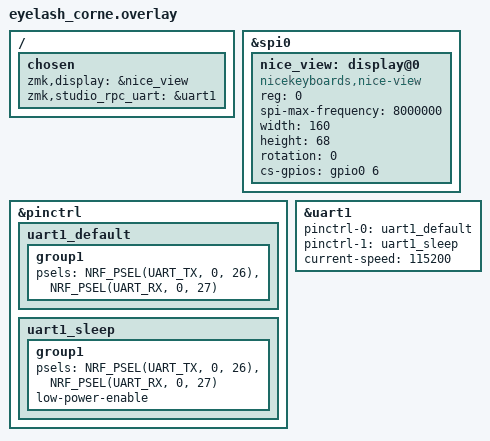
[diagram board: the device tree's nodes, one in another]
/*
 * Copyright (c) 2024 Your Name // Puedes poner tu nombre o dejarlo genérico
 * SPDX-License-Identifier: MIT
 *
 * Overlay para Nicorne Shield habilitando nice!view en SPI0.
 * ASUME que los pines SCK/MOSI/MISO son los definidos en eyelash_corne.dtsi (P0.20, P0.17, P0.25)
 * y que el pin CS es P0.06.
 */

/dts-v1/;
#include <zephyr/dt-bindings/pinctrl/nrf-pinctrl.h> // Necesario para NRF_PSEL
#include <zephyr/dt-bindings/gpio/gpio.h> // Necesario para las flags GPIO

/* Habilita el bus SPI0 (etiquetado como nice_view_spi en el .dtsi)
   y define el dispositivo nice!view conectado a él. */
&spi0 {
    status = "okay"; // Asegura que el bus SPI esté habilitado

    /* Define el dispositivo de pantalla nice!view */
    nice_view: display@0 {
        compatible = "nicekeyboards,nice-view"; // Driver específico nice!view
        reg = <0>;                        // Dirección SPI (normalmente 0 para el primer dispositivo)
        spi-max-frequency = <8000000>;    // Frecuencia SPI (8MHz es común, puedes probar 4MHz si hay problemas)
        width = <160>;                    // Ancho estándar nice!view
        height = <68>;                    // Alto estándar nice!view
        rotation = <0>;                   // Rotación (0, 90, 180, 270) - ajusta si es necesario

        cs-gpios = <&gpio0 6 GPIO_ACTIVE_HIGH>;

        /* Descomenta y ajusta si tu placa tiene control de energía dedicado para la pantalla */
        // power-gpios = <&gpioX Y GPIO_ACTIVE_HIGH>; // Reemplaza X e Y

        /* Descomenta y ajusta si tu placa tiene pin de reset dedicado para la pantalla */
        // reset-gpios = <&gpioX Z GPIO_ACTIVE_LOW>; // Reemplaza X y Z
    };
};


&pinctrl {
    uart1_default: uart1_default {
        group1 {
            psels = <NRF_PSEL(UART_TX, 0, 26)>, // P0.26
                    <NRF_PSEL(UART_RX, 0, 27)>; // P0.27
        };
    };

    uart1_sleep: uart1_sleep {
         group1 {
            psels = <NRF_PSEL(UART_TX, 0, 26)>,
                    <NRF_PSEL(UART_RX, 0, 27)>;
            low-power-enable;
        };
    };
};

&uart1 {
    pinctrl-0 = <&uart1_default>;
    pinctrl-1 = <&uart1_sleep>;
    pinctrl-names = "default", "sleep";
    status = "okay";
    current-speed = <115200>;
};


/ {
    chosen {
        /* Asegúrate de mantener las otras entradas 'chosen' que ya tenías */
        zmk,display = &nice_view;         // Pantalla nice!view
        zmk,studio_rpc_uart = &uart1;
    };
};
